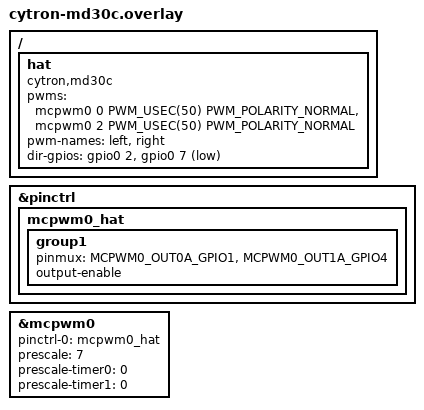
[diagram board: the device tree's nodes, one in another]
#include <zephyr/dt-bindings/pinctrl/esp32s3-pinctrl.h>
#include <zephyr/dt-bindings/pwm/pwm.h>
#include <zephyr/dt-bindings/gpio/gpio.h>

 /* XIAO     HAT (PIN, not GPIO) */
 /*  D0  --> 32  left motor  PWM */
 /*  D1  --> 37  left motor  DIR */
 /*  D3  --> 33  right motor PWM */
 /*  D8  --> 18  right motor DIR */
 /*  GND --> 34 */

&pinctrl {
	mcpwm0_hat: mcpwm0_hat {
		group1 {
			pinmux = <MCPWM0_OUT0A_GPIO1>, <MCPWM0_OUT1A_GPIO4>;
			output-enable;
		};
	};
};

&mcpwm0 {
	pinctrl-0 = <&mcpwm0_hat>;
	pinctrl-names = "default";
	prescale = <7>;
	prescale-timer0 = <0>;
	prescale-timer1 = <0>;
	status = "okay";
};

/ {
	hat {
		compatible = "cytron,md30c";
		pwms = <&mcpwm0 0 PWM_USEC(50) PWM_POLARITY_NORMAL>,
		       <&mcpwm0 2 PWM_USEC(50) PWM_POLARITY_NORMAL>;
		pwm-names = "left", "right";
		dir-gpios = <&gpio0 2 GPIO_ACTIVE_HIGH>,
			    <&gpio0 7 GPIO_ACTIVE_LOW>;
	};
};
